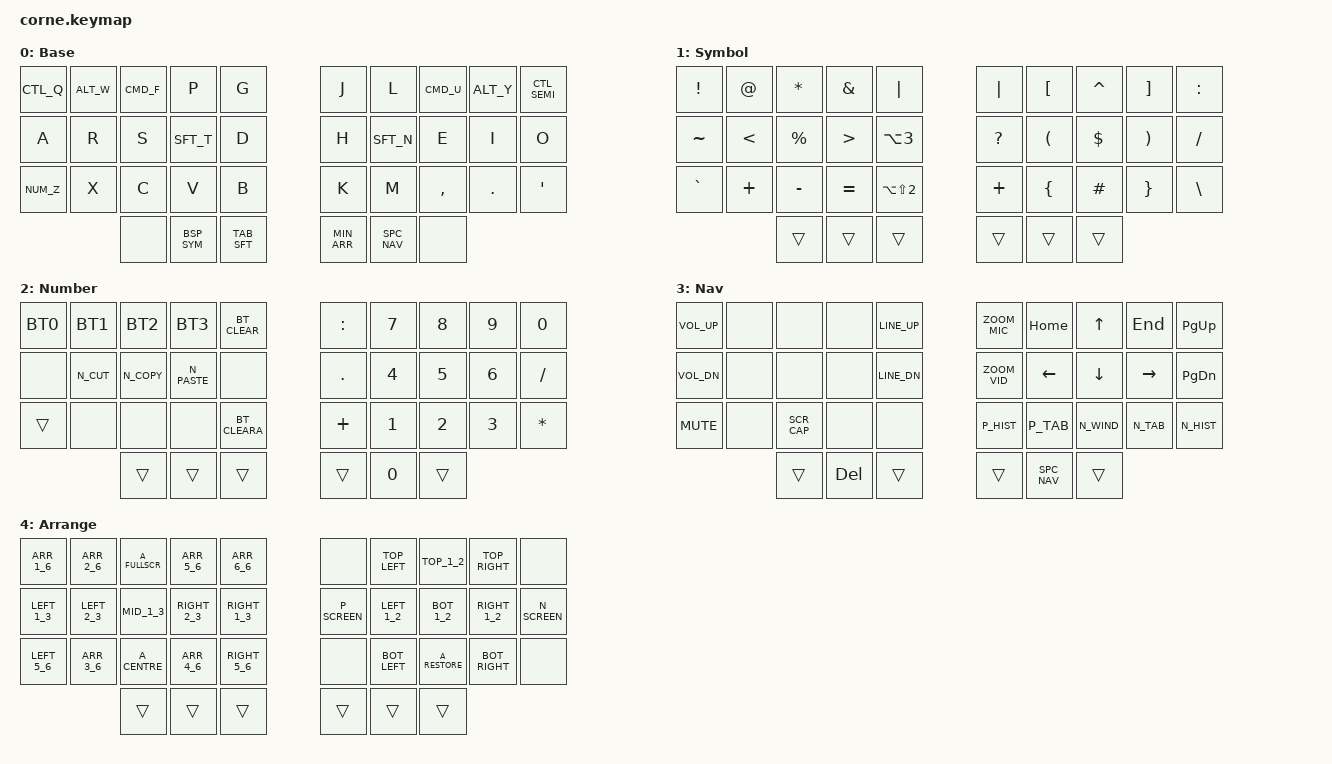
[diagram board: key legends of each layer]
/*
 * Copyright (c) 2020 The ZMK Contributors
 *
 * SPDX-License-Identifier: MIT
 */

#include <behaviors.dtsi>
#include <dt-bindings/zmk/keys.h>
#include <dt-bindings/zmk/bt.h>

#include "combos.dtsi"
#include "definitions.dtsi"
#include "tapdances.dtsi"
#include "homerow.dtsi"

/ {
        chosen {
                zmk,physical-layout = &foostan_corne_5col_layout;
        };

        keymap {
                compatible = "zmk,keymap";

                default_layer {
                        display-name = "Base";
                        bindings = <

/**
 *      DEFAULT LAYER
 *      ,-----------------------------------------------------.         .------------------------------------------------------.
 *      |   Q     |    W     |    F     |    P     |    G     |         |    J     |    L     |    U     |    Y     |    ;     |
 *      |  CTRL   |   ALT    |   CMD    |          |          |         |          |          |   CMD    |   ALT    |   CTRL   |
 *      -------------------------------------------------------         --------------------------------------------------------
 *      |   A     |    R     |    S     |    T     |    D     |         |    H     |    N     |    E     |    I     |    O     |
 *      |         |          |          |  Shift   |          |         |          |  Shift   |          |          |          |
 *      -------------------------------------------------------         --------------------------------------------------------
 *      |   Z     |    X     |    C     |    V     |    B     |         |    K     |    M     |    ,     |    .     |    '     |
 *      |  NUM    |          |          |          |          |         |          |          |          |          |          |
 *      -------------------------------------------------------         -------------------------------------------------------'
 *                                      |   BSP    |   TAB    |         |    -     |  Space   |
 *                                      |   SYM    |   SFT    |         |   Arr    |   NAV    |
 *                                      `---------------------'         `---------------------'
 **/
        
        CTL_Q      ALT_W      CMD_F      &kp P      &kp G               &kp J      &kp L      CMD_U      ALT_Y      CTL_SEMI
        &kp A      &kp R      &kp S      SFT_T      &kp D               &kp H      SFT_N      &kp E      &kp I      &kp O
        NUM_Z      &kp X      &kp C      &kp V      &kp B               &kp K      &kp M      &kp COMMA  &kp DOT    &kp SQT
                              &none      BSP_SYM    TAB_SFT             MIN_ARR    SPC_NAV  &none
                        >;
                };

                sym_layer {
                        display-name = "Symbol";
                        bindings = <
/**
 *      ,-----------------------------------------------------.         .------------------------------------------------------.
 *      |   !     |    @     |    *     |    &     |    |     |         |    |     |    [     |    ^     |    ]     |    :     |
 *      |         |          |          |          |          |         |          |          |          |          |          |
 *      -------------------------------------------------------         --------------------------------------------------------
 *      |   ~     |    <     |    %     |    >     |    £     |         |    ?     |    (     |    $     |    )     |    /     |
 *      |         |          |          |          |          |         |          |          |          |          |          |
 *      -------------------------------------------------------         --------------------------------------------------------
 *      |   `     |    +     |    -     |    =     |    €     |         |    +     |    {     |    #     |    }     |    \     |
 *      |         |          |          |          |          |         |          |          |          |          |          |
 *      -------------------------------------------------------         --------------------------------------------------------
 *                                      |   BSP    |   TAB    |         |    -     |  Space   |
 *                                      |   SYM    |   SFT    |         |   Arr    |   NAV    |
 *                                      `---------------------'         `---------------------'
 **/

        &kp EXCL   &kp AT     &kp ASTRK  &kp AMPS   &kp PIPE            &kp PIPE   &kp LBKT   &kp CARET  &kp RBKT   &kp COLON
        &kp TILDE  &kp LT     &kp PRCNT  &kp GT     &kp LA(N3)          &kp QMARK  &kp LPAR   &kp DLLR   &kp RPAR   &kp FSLH
        &kp GRAVE  &kp PLUS   &kp MINUS  &kp EQUAL  &kp LA(LS(N2))      &kp PLUS   &kp LBRC   &kp HASH   &kp RBRC   &kp BSLH
                              &trans     &trans     &trans              &trans     &trans     &trans
                        >;
                };

                num_layer {
                        display-name = "Number";
                        bindings = <
/**
 *      ,-----------------------------------------------------.         .------------------------------------------------------.
 *      |  BT 0   |   BT 1   |   BT 2   |   BT 3   |   BT     |         |    :     |    7     |    8     |    9     |    0     |
 *      |         |          |          |          |  clear   |         |          |          |          |          |          |
 *      -------------------------------------------------------         --------------------------------------------------------
 *      |         |   CUT    |   COPY   |  PASTE   |          |         |    .     |    4     |    5     |    6     |    /     |
 *      |         |          |          |          |          |         |          |          |          |          |          |
 *      -------------------------------------------------------         --------------------------------------------------------
 *      |  NUM    |          |          |          |    BT    |         |    +     |    1     |    2     |    3     |    *     |
 *      |         |          |          |          | ClearAll |         |          |          |          |          |          |
 *      -------------------------------------------------------         --------------------------------------------------------
 *                                      |   BSP    |   TAB    |         |    -     |    0     |
 *                                      |   SYM    |   SFT    |         |   Arr    |          |
 *                                      `---------------------'         `---------------------'
 **/
 
        BT0        BT1        BT2        BT3        BT_CLEAR            &kp COLON  &kp N7     &kp N8     &kp N9     &kp N0 
        &none      N_CUT      N_COPY     N_PASTE    &none               &kp DOT    &kp N4     &kp N5     &kp N6     &kp FSLH 
        &trans     &none      &none      &none      BT_CLEARA               &kp PLUS   &kp N1     &kp N2     &kp N3     &kp ASTRK
                              &trans     &trans     &trans              &trans     &kp N0     &trans
                        >;
                };
        
                nav_layer {

                        display-name = "Nav";
                        bindings = <
/**
 *      ,-----------------------------------------------------.         .------------------------------------------------------.
 *      |  Vol +  |          |          |          |  Xcode   |         |  Zoom    |   Home   |    Up    |   End    | Page Up  |
 *      |         |          |          |          |  Line Up |         |  Mic     |          |          |          |          |
 *      -------------------------------------------------------         --------------------------------------------------------
 *      |  Vol -  |          |          |          |  Xcode   |         |  Zoom    |   Left   |   Down   |  Right   | Page Dn  |
 *      |         |          |          |          |  Line Dn |         |  Video   |          |          |          |          |
 *      -------------------------------------------------------         --------------------------------------------------------
 *      |  Mute   |          |  Screen  |          |          |         |  Prev    |   Prev   |   Next   |  Next    |   Next   |
 *      |         |          | Capture  |          |          |         | History  |   Tab    | Window   |  Tab     |  History |
 *      -------------------------------------------------------         --------------------------------------------------------
 *                                      |   BSP    |   TAB    |         |    -     |  Space   |
 *                                      |   SYM    |   SFT    |         |   Arr    |   NAV    |
 *                                      `---------------------'         `---------------------'
 **/
        
        &kp C_VOL_UP   &none      &none      &none      LINE_UP             ZOOM_MIC   &kp HOME   &kp UP     &kp END    &kp PAGE_UP
        &kp C_VOL_DN   &none      &none      &none      LINE_DN             ZOOM_VID   &kp LEFT   &kp DOWN   &kp RIGHT  &kp PAGE_DOWN
        &kp C_MUTE     &none      SCR_CAP    &none      &none               P_HIST     P_TAB      N_WIND     N_TAB      N_HIST
                              &trans     &kp DEL    &trans              &trans     SPC_NAV     &trans
                        >;
                };

                arr_layer {
                        display-name = "Arrange";
                        bindings = <
/**
 *      ,-----------------------------------------------------.         .------------------------------------------------------.
 *      |  1/6th  |  2/6th   |  Full    |  5/6th   |  6/6th   |         |          |   Top    |   Top    |   Top    |          |
 *      |         |          |  Screen  |          |          |         |          |   Left   |   Half   |  Right   |          |
 *      -------------------------------------------------------         --------------------------------------------------------
 *      | L 1/3rd | L 2/3rds | C 1/3rd  | R 2/3rds | R 1/3rd  |         |  Prev    |   Left   |   Down   |  Right   |  Next    |
 *      |         |          |          |          |          |         | Screen   |   Half   |          |  Half    |  Screen  |
 *      -------------------------------------------------------         --------------------------------------------------------
 *      | L 5/6th |  3/6th   |  Centre  |  4/6th   | R 5/6th  |         |          |  Bottom  |  Bottom  |  Bottom  |          |
 *      |         |          |          |          |          |         |          |  Left    |  Half    |  Right   |          |
 *      -------------------------------------------------------         --------------------------------------------------------
 *                                      |   BSP    |   TAB    |         |    -     |  Space   |
 *                                      |   SYM    |   SFT    |         |   Arr    |   NAV    |
 *                                      `---------------------'         `---------------------'
 **/

        ARR_1_6    ARR_2_6    A_FULLSCR  ARR_5_6    ARR_6_6             &none      TOP_LEFT   TOP_1_2    TOP_RIGHT  &none
        LEFT_1_3   LEFT_2_3   MID_1_3    RIGHT_2_3  RIGHT_1_3           P_SCREEN   LEFT_1_2   BOT_1_2    RIGHT_1_2  N_SCREEN
        LEFT_5_6   ARR_3_6    A_CENTRE   ARR_4_6    RIGHT_5_6           &none      BOT_LEFT   A_RESTORE  BOT_RIGHT  &none
                              &trans     &trans     &trans              &trans     &trans     &trans
                        >;
                };
        };
};
